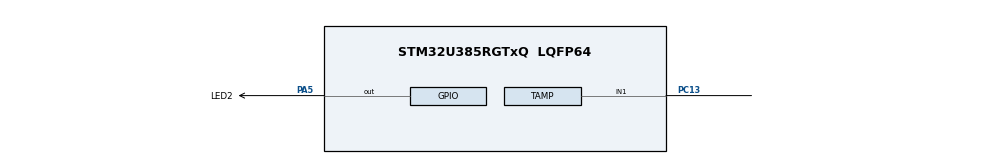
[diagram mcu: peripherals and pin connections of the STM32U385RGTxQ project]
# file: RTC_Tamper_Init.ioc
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CORTEX_M33_NS.userName=CORTEX_M33
Mcu.Family=STM32U3
Mcu.Name=STM32U385RGTxQ
Mcu.Package=LQFP64
NVIC.PriorityGroup=NVIC_PRIORITYGROUP_4
PA5.GPIO_Label=LED2
PA5.Signal=GPIO_Output
PC13.Mode=Tamper_1_enabled0
PC13.Signal=TAMP_IN1
PC14-OSC32_IN\ (PC14).Mode=LSE-External-Oscillator-for-RTC
PC14-OSC32_IN\ (PC14).Signal=RCC_OSC32_IN
PC15-OSC32_OUT\ (PC15).Mode=LSE-External-Oscillator-for-RTC
PC15-OSC32_OUT\ (PC15).Signal=RCC_OSC32_OUT
ProjectManager.HeapSize=0x200
ProjectManager.StackSize=0x400
ProjectManager.TargetToolchain=EWARM V9.20
RCC.ADCFreq_Value=96000000
RCC.AHBFreq_Value=96000000
RCC.APB1Freq_Value=96000000
RCC.APB1TimFreq_Value=96000000
RCC.APB2Freq_Value=96000000
RCC.APB2TimFreq_Value=96000000
RCC.APB3Freq_Value=96000000
RCC.CortexFreq_Value=12000000
RCC.HCLKFreq_Value=96000000
RCC.HSE_VALUE=16000000
RCC.HSI48_VALUE=48000000
RCC.HSI_VALUE=16000000
RCC.LSIDIV_VALUE=32000
RCC.MSISDIV=RCC_MSI_DIV1
RCC.RTCClockSelection=RCC_RTCCLKSOURCE_LSE
RCC.SYSCLKFreq_VALUE=96000000
RCC.USBFreq_Value=96000000
VP_ICACHE_VS_ICACHE.Mode=DirectMappedCache
VP_PWR_VS_DBSignals.Mode=DisableDeadBatterySignals
VP_PWR_VS_LPOM.Mode=PowerOptimisation
VP_PWR_VS_SECSignals.Mode=Security/Privilege
VP_RTC_VS_RTC_Activate.Mode=RTC_Enabled
board=custom

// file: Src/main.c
/* USER CODE BEGIN Header */
/**
  ******************************************************************************
  * @file    Examples_LL/RTC/RTC_Tamper_Init/Src/main.c
  * @author  MCD Application Team
  * @brief   This sample code shows how to use STM32U3xx RTC LL API
  *          to write/read data to/from RTC Backup data registers and demonstrates
  *          the Tamper detection feature.
  ******************************************************************************
  * @attention
  *
  * Copyright (c) 2024 STMicroelectronics.
  * All rights reserved.
  *
  * This software is licensed under terms that can be found in the LICENSE file
  * in the root directory of this software component.
  * If no LICENSE file comes with this software, it is provided AS-IS.
  *
  ******************************************************************************
  */
/* USER CODE END Header */
#include "main.h"

/* USER CODE BEGIN PD */

#define BACKUP_COUNT 5
/* USER CODE END PD */

/* USER CODE BEGIN PV */

__IO FlagStatus TamperStatus = RESET;

/* Backup registers table */
uint32_t aBKPDataReg[BACKUP_COUNT] =
{
  LL_RTC_BKP_DR0,  LL_RTC_BKP_DR1,  LL_RTC_BKP_DR2,
  LL_RTC_BKP_DR3,  LL_RTC_BKP_DR4
};

/* USER CODE END PV */

void SystemClock_Config(void);
static void MX_GPIO_Init(void);
static void MX_RTC_Init(void);
static void MX_TAMP_RTC_Init(void);
static void MX_ICACHE_Init(void);
/* USER CODE BEGIN PFP */
void     LED_On(void);
void     LED_Blinking(uint32_t Period);
/* USER CODE END PFP */

int main(void)
{

  /* USER CODE BEGIN 1 */

  register uint32_t index = 0;

  /* USER CODE END 1 */

  /* MCU Configuration--------------------------------------------------------*/

  /* Reset of all peripherals, Initializes the Flash interface and the Systick. */

  /* System interrupt init*/
  NVIC_SetPriorityGrouping(NVIC_PRIORITYGROUP_4);

  /* SysTick_IRQn interrupt configuration */
  NVIC_SetPriority(SysTick_IRQn, NVIC_EncodePriority(NVIC_GetPriorityGrouping(),15, 0));

  /* Configure the system clock */
  SystemClock_Config();

  /* Initialize all configured peripherals */
  MX_GPIO_Init();
  MX_RTC_Init();
  MX_TAMP_RTC_Init();
  MX_ICACHE_Init();
  /* USER CODE BEGIN 2 */
  LL_RTC_ClearFlag_TAMP1(RTC);
  /* Write Data on the Back Up registers  */
  for (index = 0; index < BACKUP_COUNT; index++)
  {
    LL_RTC_BKP_SetRegister(RTC, aBKPDataReg[index], 0xDF59 + (index * 0x5A));
  }

  /* Check Data is stored on the Back Up registers */
  for (index = 0; index < BACKUP_COUNT; index++)
  {
    if (LL_RTC_BKP_GetRegister(RTC, aBKPDataReg[index]) != (0xDF59 + (index * 0x5A)))
    {
      LED_Blinking(LED_BLINK_ERROR);
    }
  }

  /* Wait for Tamper detection */
  while (TamperStatus != SET)
  {
    LL_GPIO_TogglePin(LED2_GPIO_Port, LED2_Pin);
    LL_mDelay(LED_BLINK_FAST);
  }

  /* LD2 On: Tamper button pressed */
  LED_On();

  /* USER CODE END 2 */

  /* Infinite loop */
  while (1)
  {

  }
}

void SystemClock_Config(void)
{
  /** Enable Epod Booster
  */
  LL_AHB1_GRP2_EnableClock(LL_AHB1_GRP2_PERIPH_PWR);
  LL_RCC_SetEPODBoosterClkSource(LL_RCC_EPODBOOSTCLKSRCE_MSIS);
  LL_RCC_SetEPODBoosterClkPrescaler(LL_RCC_EPODBOOSTCLKPRESCAL_1);
  LL_PWR_EnableEPODBooster();
  while(LL_PWR_IsActiveFlag_BOOST() != 1U)
  {
  }

  /** Configure the main internal regulator output voltage
  */
  LL_PWR_SetRegulVoltageScaling(LL_PWR_REGU_VOLTAGE_SCALE1);
  while(LL_PWR_GetRegulCurrentVOS() != LL_PWR_REGU_VOLTAGE_SCALE1)
  {
  }

  /** Set Flash latency before switching to MSIS
  */
  LL_FLASH_SetLatency(LL_FLASH_LATENCY_2);
  while(LL_FLASH_GetLatency() != LL_FLASH_LATENCY_2)
  {
  }

  LL_PWR_EnableBkUpAccess();
  while (LL_PWR_IsEnabledBkUpAccess () == 0U)
  {
  }

  /* Activate MSIS as source */
  LL_RCC_MSIS_SetClockSource(LL_RCC_MSIS_CLOCK_SOURCE_RC0);
  LL_RCC_MSIS_SetClockDivision(LL_RCC_MSIS_CLOCK_SOURCE_RC_DIV_1);
  LL_RCC_MSI_SetMSIxClockRange();
  LL_RCC_LSE_SetDriveCapability(LL_RCC_LSEDRIVE_LOW);
  LL_RCC_LSE_Enable();

   /* Wait till LSE is ready */
  while(LL_RCC_LSE_IsReady() != 1)
  {
  }

  LL_RCC_SetSysClkSource(LL_RCC_SYS_CLKSOURCE_MSIS);

   /* Wait till System clock is ready */
  while(LL_RCC_GetSysClkSource() != LL_RCC_SYS_CLKSOURCE_MSIS)
  {
  }

  LL_RCC_SetAHBPrescaler(LL_RCC_HCLK_SYSCLK_DIV_1);
  LL_RCC_SetAPB1Prescaler(LL_RCC_APB1_HCLK_DIV_1);
  LL_RCC_SetAPB2Prescaler(LL_RCC_APB2_HCLK_DIV_1);
  LL_RCC_SetAPB3Prescaler(LL_RCC_APB3_HCLK_DIV_1);

  LL_Init1msTick(96000000);

  LL_SetSystemCoreClock(96000000);
}

static void MX_ICACHE_Init(void)
{

  /** Enable instruction cache in 1-way (direct mapped cache)
  */
  LL_ICACHE_SetMode(LL_ICACHE_1WAY);
  LL_ICACHE_Enable();

}

static void MX_RTC_Init(void)
{

  LL_RTC_InitTypeDef RTC_InitStruct = {0};

  if(LL_RCC_GetRTCClockSource(LL_RCC_RTC_CLKSOURCE) != LL_RCC_RTC_CLKSOURCE_LSE)
  {
    FlagStatus pwrclkchanged = RESET;
    /* Update LSE configuration in Backup Domain control register */
    /* Requires to enable write access to Backup Domain if necessary */
    if (LL_AHB1_GRP2_IsEnabledClock(LL_AHB1_GRP2_PERIPH_PWR) != 1U)
    {
      /* Enables the PWR Clock and Enables access to the backup domain */
      LL_AHB1_GRP2_EnableClock(LL_AHB1_GRP2_PERIPH_PWR);
      pwrclkchanged = SET;
    }
    if (LL_PWR_IsEnabledBkUpAccess () != 1U)
    {
      /* Enable write access to Backup domain */
      LL_PWR_EnableBkUpAccess();
      while (LL_PWR_IsEnabledBkUpAccess () == 0U)
      {
      }
    }
    LL_RCC_ForceBackupDomainReset();
    LL_RCC_ReleaseBackupDomainReset();
  LL_RCC_LSE_SetDriveCapability(LL_RCC_LSEDRIVE_LOW);
    LL_RCC_LSE_Enable();

   /* Wait till LSE is ready */
    while(LL_RCC_LSE_IsReady() != 1)
    {
    }
    LL_RCC_SetRTCClockSource(LL_RCC_RTC_CLKSOURCE_LSE);
    /* Restore clock configuration if changed */
    if (pwrclkchanged == SET)
    {
      LL_AHB1_GRP2_DisableClock(LL_AHB1_GRP2_PERIPH_PWR);
    }
  }

  /* Peripheral clock enable */
  LL_RCC_RTC_ClockEnable();
  LL_APB1_GRP1_EnableClock(LL_APB1_GRP1_PERIPH_RTCAPB);

  /* USER CODE BEGIN RTC_Init 1 */

  /* Enables the PWR Clock and Enables access to the backup domain */
  LL_AHB1_GRP2_EnableClock(LL_AHB1_GRP2_PERIPH_PWR);

  LL_PWR_EnableBkUpAccess();
  /* USER CODE END RTC_Init 1 */
  RTC_InitStruct.HourFormat = LL_RTC_HOURFORMAT_24HOUR;
  RTC_InitStruct.AsynchPrescaler = 127;
  RTC_InitStruct.SynchPrescaler = 255;
  LL_RTC_Init(RTC, &RTC_InitStruct);
  LL_RTC_SetBackupRegisterPrivilege(RTC, LL_RTC_PRIVILEGE_BKUP_ZONE_NONE);
  LL_RTC_SetBackupRegProtection(RTC, LL_RTC_BKP_DR0, LL_RTC_BKP_DR0);
  LL_RTC_SetRtcPrivilege(RTC, LL_RTC_PRIVILEGE_FULL_NO);
  /* USER CODE BEGIN RTC_Init 2 */
  /* Enable IT TAMPER */
  LL_RTC_EnableIT_TAMP1(RTC);

  /* Configure the NVIC for RTC Tamper */
  NVIC_SetPriority(TAMP_IRQn, 0x0F);
  NVIC_EnableIRQ(TAMP_IRQn);

  /* RTC Tamper Interrupt Configuration: EXTI configuration */
  LL_EXTI_EnableIT_0_31(LL_EXTI_LINE_13);
  LL_EXTI_EnableRisingTrig_0_31(LL_EXTI_LINE_13);

  /* Clear the Tamper interrupt pending bit */
  LL_RTC_ClearFlag_TAMP1(RTC);
  /* USER CODE END RTC_Init 2 */

}

static void MX_TAMP_RTC_Init(void)
{

  /* Peripheral clock enable */

  /** Enable the RTC Tamper 1
  */
  LL_RTC_TAMPER_Enable(RTC, LL_RTC_TAMPER_1);
  LL_RTC_TAMPER_SetFilterCount(RTC, LL_RTC_TAMPER_FILTER_DISABLE);
  LL_RTC_TAMPER_SetPrecharge(RTC, LL_RTC_TAMPER_DURATION_1RTCCLK);
  LL_RTC_TAMPER_SetSamplingFreq(RTC, LL_RTC_TAMPER_SAMPLFREQDIV_32768);
  LL_RTC_TAMPER_DisableMask(RTC, LL_RTC_TAMPER_MASK_TAMPER1);
  LL_RTC_TAMPER_EnableEraseBKP(RTC, LL_RTC_TAMPER_NOERASE_TAMPER1);
  LL_RTC_TAMPER_EnablePullUp(RTC);

}

static void MX_GPIO_Init(void)
{
  LL_GPIO_InitTypeDef GPIO_InitStruct = {0};

  /* GPIO Ports Clock Enable */
  LL_AHB2_GRP1_EnableClock(LL_AHB2_GRP1_PERIPH_GPIOC);
  LL_AHB2_GRP1_EnableClock(LL_AHB2_GRP1_PERIPH_GPIOA);

  /**/
  LL_GPIO_ResetOutputPin(LED2_GPIO_Port, LED2_Pin);

  /**/
  GPIO_InitStruct.Pin = LED2_Pin;
  GPIO_InitStruct.Mode = LL_GPIO_MODE_OUTPUT;
  GPIO_InitStruct.Speed = LL_GPIO_SPEED_FREQ_LOW;
  GPIO_InitStruct.OutputType = LL_GPIO_OUTPUT_PUSHPULL;
  GPIO_InitStruct.Pull = LL_GPIO_PULL_NO;
  LL_GPIO_Init(LED2_GPIO_Port, &GPIO_InitStruct);

}

/* USER CODE BEGIN 4 */

/**
  * @brief  Turn-on LD2.
  * @param  None
  * @retval None
  */
void LED_On(void)
{
  /* Turn LD2 on */
  LL_GPIO_SetOutputPin(LED2_GPIO_Port, LED2_Pin);
}

/**
  * @brief  Set LD2 to Blinking mode for an infinite loop (toggle period based on value provided as input parameter).
  * @param  Period : Period of time (in ms) between each toggling of LED
  *   This parameter can be user defined values. Pre-defined values used in that example are :
  *     @arg LED_BLINK_FAST : Fast Blinking
  *     @arg LED_BLINK_SLOW : Slow Blinking
  *     @arg LED_BLINK_ERROR : Error specific Blinking
  * @retval None
  */
void LED_Blinking(uint32_t Period)
{
  /* Toggle IO in an infinite loop */
  while (1)
  {
    LL_GPIO_TogglePin(LED2_GPIO_Port, LED2_Pin);
    LL_mDelay(Period);
  }
}

/******************************************************************************/
/*   USER IRQ HANDLER TREATMENT                                               */
/******************************************************************************/
/**
  * @brief  Tamper event callback function
  * @param  None
  * @retval None
  */
void Tamper_Callback(void)
{
  register uint32_t index = 0;

  /* Deactivate the tamper */
  LL_RTC_TAMPER_Disable(RTC, LL_RTC_TAMPER_1);

  /* Check Data is cleared on the Back Up registers */
  for (index = 0; index < BACKUP_COUNT; index++)
  {
    if (LL_RTC_BKP_GetRegister(RTC, aBKPDataReg[index]) != 0x00)
    {
      LED_Blinking(LED_BLINK_ERROR);
    }
  }
  TamperStatus = SET;
}

/* USER CODE END 4 */

void Error_Handler(void)
{
}
